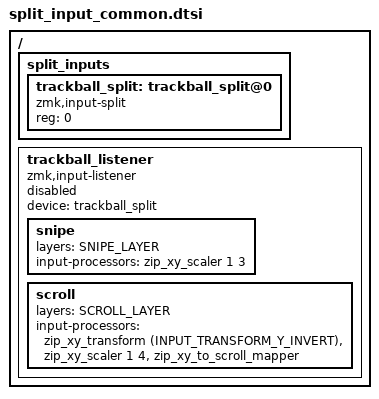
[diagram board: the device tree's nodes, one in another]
#include <dt-bindings/zmk/input_transform.h>
#include <input/processors.dtsi>

#define SCROLL_LAYER 6
#define SNIPE_LAYER 7

/ {
  split_inputs {
    #address-cells = <1>;
    #size-cells = <0>;

    trackball_split: trackball_split@0 {
      compatible = "zmk,input-split";
      reg = <0>;
    };
  };

  trackball_listener: trackball_listener {
    compatible = "zmk,input-listener";
    status = "disabled";
    device = <&trackball_split>;

    snipe {
      layers = <SNIPE_LAYER>;
      input-processors = <&zip_xy_scaler 1 3>;
    };

    scroll {
      layers = <SCROLL_LAYER>;
      input-processors = <&zip_xy_transform (INPUT_TRANSFORM_Y_INVERT)>, <&zip_xy_scaler 1 4>, <&zip_xy_to_scroll_mapper>;
    };
  };
};
